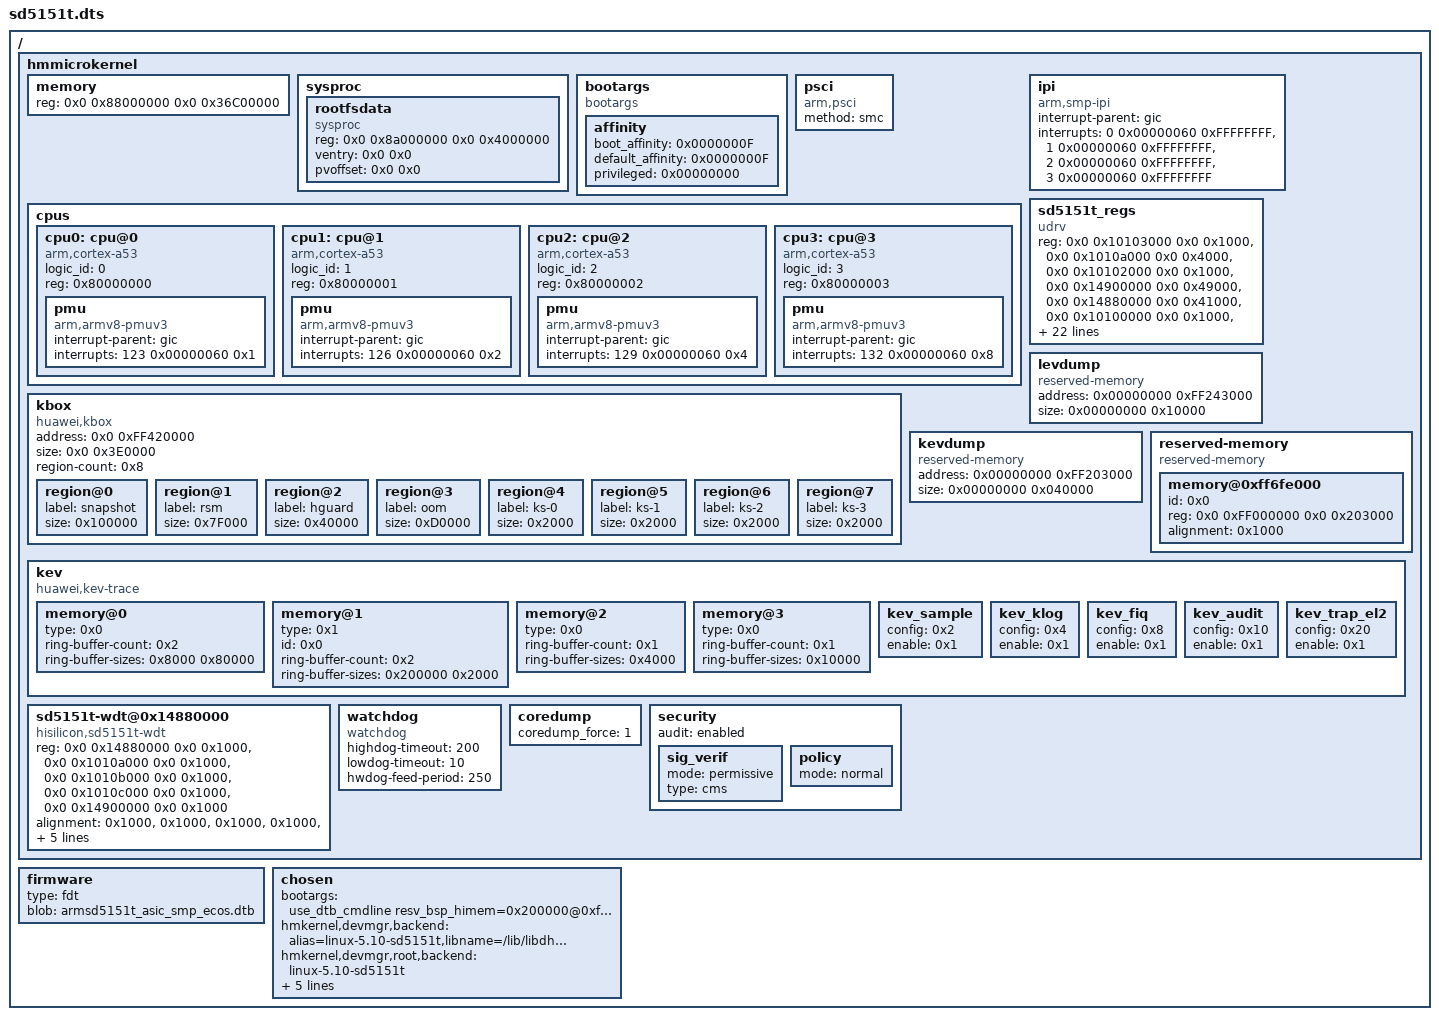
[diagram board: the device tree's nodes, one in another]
/*
 * Device Tree for SD5151T Board
 */

/dts-v1/;

/include/ "sd5151t.dtsi"
/ {
	hmmicrokernel {
		memory {
			device_type = "memory";
			/*
                         * deployment for physical memory
                         *
                         * +----------------+ 0xFFF00000
                         * | resv bsp himem | 1M
                         * +----------------+ 0xFFE00000
                         *         |
                         * +----------------+ 0xFF800000
                         * |     kbox       | 3968K
                         * +----------------+ 0xFF420000
                         * |     ekbox      | 128K
                         * +----------------+ 0xFF400000
                         * |     klog       | 4M
                         * +----------------+ 0xFF000000
                         * |     unused     | 4M
                         * +----------------+ 0xFEC00000
                         * |      shm       | 32M+8K+4K    -->0xFEC00000 -->0xFEC00000
                         * +----------------+ 0xFCBFD000          ^             ^
                         * |                | 1012K               |             |
                         * + third-party vm + 0xFCB00000        1024M           |
                         * | (guest mem01)  | 991M                |           1900M
                         * |                | (final: 1332M)      V             |
                         * +----------------+ 0xBEC00000   -->0xBEC00000        |
                         * |      host      | 876M                              |
                         * |  (include hpe) | (final: 567M)                     V
                         * +----------------+ 0x88000000 -->0x88000000 -->0x88000000
                         * |    lsw sdk     | 128M
                         * +----------------+ 0x80000000
                         */
			reg = <0x0 0x88000000 0x0 0x36C00000>;
		};

		sysproc {
			/* Describe board boot param rootfs in top level dts */
			rootfsdata {
				compatible = "sysproc", "rootfs";
				reg = <0x0 0x8a000000 0x0 0x4000000>;
				ventry = <0x0 0x0>;
				/* filled by bootloader */
				pvoffset = <0x0 0x0>;
			};
		};

		bootargs {
			compatible = "bootargs";
			affinity {
				boot_affinity = <0x0000000F>;			/* CPU 0, 1, 2, 3 */
				default_affinity = <0x0000000F>;		/* CPU 0, 1, 2, 3 */
				privileged = <0x00000000>;		/* no privileged_affinity in default */
			};
		};

		psci {
			compatible = "arm,psci";
			method = "smc";
		};

		cpus {
			#address-cells = <1>;
			#size-cells = <0>;

			cpu0: cpu@0 {
				compatible = "arm,cortex-a53", "arm,armv8";
				device_type = "cpu";
				logic_id = <0>;
				reg = <0x80000000>;
				pmu {
					compatible = "arm,armv8-pmuv3";
					interrupt-parent = <&gic>;
					/* SPI 64: PMUIRQ, group default, prio:0x60 */
					interrupts = <123 0x00000060 0x1>;
				};
			};
			cpu1: cpu@1 {
				compatible = "arm,cortex-a53", "arm,armv8";
				device_type = "cpu";
				logic_id = <1>;
				reg = <0x80000001>;
				pmu {
					compatible = "arm,armv8-pmuv3";
					interrupt-parent = <&gic>;
					interrupts = <126 0x00000060 0x2>;
				};
			};
			cpu2: cpu@2 {
				compatible = "arm,cortex-a53", "arm,armv8";
				device_type = "cpu";
				logic_id = <2>;
				reg = <0x80000002>;
				pmu {
					compatible = "arm,armv8-pmuv3";
					interrupt-parent = <&gic>;
					interrupts = <129 0x00000060 0x4>;
				};
			};
			cpu3: cpu@3 {
				compatible = "arm,cortex-a53", "arm,armv8";
				device_type = "cpu";
				logic_id = <3>;
				reg = <0x80000003>;
				pmu {
					compatible = "arm,armv8-pmuv3";
					interrupt-parent = <&gic>;
					interrupts = <132 0x00000060 0x8>;
				};
			};
		};

		ipi {
			/* smp ipi */
			compatible = "arm,smp-ipi";

			interrupt-parent = <&gic>;

			/* interrupt settings:
			 * 1st cell: real hardware irq number
			 *     ARM recommendation: ID 0-7 for Non-Secure;
			 *                         ID 8-15 for Secure Interrupt
			 * 2nd cell: interrupt config
			 *     bit [27:26]: Group setting
			 *     bit [24]: Trigger Type
			 *     bit [23:8]: Reserved
			 *     bit [7:0]: Priority
			 * 3rd cell: interrupt target config
			 *     Warning: Send to all cpus by default
			 */
			interrupts =	<0 0x00000060 0xFFFFFFFF>, /* IPI_RESCHEDULE */
					<1 0x00000060 0xFFFFFFFF>, /* IPI_CALL_FUNC */
					<2 0x00000060 0xFFFFFFFF>, /* IPI_CPU_STOP */
					<3 0x00000060 0xFFFFFFFF>; /* IPI_VNOTIFY */
		};

		sd5151t_regs {
			compatible = "udrv";
			#address-cells = <2>;
			#size-cells = <2>;
			reg =	<0x0 0x10103000 0x0 0x1000>, /* timer */
				<0x0 0x1010a000 0x0 0x4000>, /* gpio */
				<0x0 0x10102000 0x0 0x1000>, /* bus_timer */
				<0x0 0x14900000 0x0 0x49000>,
				<0x0 0x14880000 0x0 0x41000>,
				<0x0 0x10100000 0x0 0x1000>,
				<0x0 0x10120000 0x0 0x2000>,
				<0x0 0x10121000 0x0 0x1000>, /* i2c */
				<0x0 0x10144000 0x0 0x10000>,
				<0x0 0x30000000 0x0 0x400000>,
				<0x0 0x48000000 0x0 0x400000>,
				<0x0 0x1014c000 0x0 0x10000>,
				<0x0 0x14880000 0x0 0x1000>,
				<0x0 0x14900000 0x0 0x1000>,
				<0x0 0x60000000 0x0 0x400000>, /* pcie */
				<0x0 0x15200000 0x0 0x1000>,
				<0x0 0x14880000 0x0 0x1000>, /* ata */
				<0x0 0xFF420000 0x0 0x003E0000>, /* kbox */
				<0x0 0xFF243000 0x0 0x10000>, /* levdump */
				<0x0 0xFF203000 0x0 0x40000>, /* kevdump */
				<0x0 0xff800000 0x0 0x800000>, /* bsp_himem */
				<0x0 0x10000000 0x0 0x6000000>, /* sdk */
				<0x0 0x10700000 0x0 0x10000>,
				<0x0 0x10900000 0x0 0x100000>, /* FMC */
				<0x0 0x10100000 0x0 0x6000000>, /* fmea */
				<0x0 0x50100000 0x0 0x2000>,
				<0x0 0x10106000 0x0 0x4000>, /* uart0-uart3 */
				<0x0 0x15100000 0x0 0x100000>; /* usb3.0 */
		};

		kbox {
			compatible = "huawei,kbox";
			address = <0x0 0xFF420000>;
			size = <0x0 0x3E0000>;
			region-count= <0x8>;
			region@0 {
				label = "snapshot";
				size = <0x100000>;
			};
			region@1 {
				label = "rsm";
				size = <0x7F000>;
			};
			region@2 {
				label = "hguard";
				size = <0x40000>;
			};
			region@3 {
				label = "oom";
				size = <0xD0000>;
			};
			region@4 {
				label = "ks-0";
				size = <0x2000>;
			};
			region@5 {
				label = "ks-1";
				size = <0x2000>;
			};
			region@6 {
				label = "ks-2";
				size = <0x2000>;
			};
			region@7 {
				label = "ks-3";
				size = <0x2000>;
			};
		};

		levdump {
			compatible = "reserved-memory";
			address = <0x00000000 0xFF243000>;
			size = <0x00000000 0x10000>;
		};

		kevdump {
			compatible = "reserved-memory";
			address = <0x00000000 0xFF203000>;
			size = <0x00000000 0x040000>;
		};

		reserved-memory {
			compatible = "reserved-memory";
			#address-cells = <2>;
			#size-cells = <2>;
			memory@0xff6fe000 {
				id = <0x0>;
				reg = <0x0 0xFF000000 0x0 0x203000>;
				alignment = <0x1000>;
			};
		};

		kev {
			compatible = "huawei,kev-trace";

			memory@0 {
				type = <0x0>;
				ring-buffer-count = <0x2>;
				/*
				 * ring buffer 0: 32K
				 * ring buffer 1: 512K (sample)
				 */
				ring-buffer-sizes = <0x8000 0x80000>;
			};

			memory@1 {
				type = <0x1>; /* reserved memory */
				id = <0x0>;
				ring-buffer-count = <0x2>;
				/*
				 * Only ring buffer DATA sizes. Memory head and ring
				 * buffer heads are not included.
				 * ring buffer 2: 2MB(klog)
				 * ring buffer 3: 8K(fiq)
				 */
				ring-buffer-sizes = <0x200000 0x2000>;
			};

			memory@2 {
				type = <0x0>;
				ring-buffer-count = <0x1>;
				/*
				 * ring buffer 4: 16K(audit)
				 */
				ring-buffer-sizes = <0x4000>;
			};

			memory@3 {
				type = <0x0>; /* normal memory */
				ring-buffer-count = <0x1>;
				/*
				 * ring buffer 5: 64K(trap_el2)
				 */
				ring-buffer-sizes = <0x10000>;
			};

			kev_sample {
				config = <0x2>;
				enable = <0x1>;
			};
			kev_klog {
				config = <0x4>;
				enable = <0x1>;
			};
			kev_fiq {
				config = <0x8>;
				enable = <0x1>;
			};
			kev_audit {
				config = <0x10>;
				enable = <0x1>;
			};
			kev_trap_el2 {
				config = <0x20>;
				enable = <0x1>;
			};
		};

		/* SD5151T CPU watchdog */
		sd5151t-wdt@0x14880000 {
			compatible = "hisilicon,sd5151t-wdt";
			#address-cells = <2>;
			#size-cells = <2>;

			reg = <0x0 0x14880000 0x0 0x1000>,
			      /*
			       * SD5151T ext watchdog based on GPIO, cannot
			       * configure the timeout-sec for it.
			       */
			      <0x0 0x1010a000 0x0 0x1000>, /* GPIO  0 ~ 31 */
			      <0x0 0x1010b000 0x0 0x1000>, /* GPIO 32 ~ 63 */
			      <0x0 0x1010c000 0x0 0x1000>, /* GPIO 64 ~ 95 */
			      <0x0 0x14900000 0x0 0x1000>; /* IOMUX_DIO */
			alignment = <0x1000>, <0x1000>, <0x1000>, <0x1000>, <0x1000>;

			/*
			 * Configure the GPIO Pins for the SD5151T ext watchdog
			 *
			 * 1st cell: GPIO Pin for resetting the SD5151T ext watchdog.
			 *
			 * 2nd cell: GPIO Pin for triggering the interrupt when
			 *           the SD5151T ext watchdog timeout.
			 *
			 * 3rd cell: GPIO Pin for enabling the SD5151T ext watchdog.
			 *
			 * Currently the configurations for AR502H are <18 21 91>.
			 */
			ext-wdt-gpio = <18 21 91>;

			interrupt-parent = <&gic>;
			/*
			 * SGI number 6 is configured as a Group 0 interrupt in
			 * ATF. If the SD5151T ext watchdog timeout, It would be
			 * triggered to help the specific CPUs dump the lastword.
			 *
			 * SPI number 45 is triggered when the SD5151T ext watchdog
			 * timeout and configured as a Group 0 interrupt in ATF.
			 */
			interrupts = <6 0x00000060 0xFFFFFFFF>,  /* lastword ipi */
				     <45 0x00000060 0xFFFFFFFF>; /* gpio0_int */
		};
		watchdog {
			compatible = "watchdog";
			/* reserve 200s for hguard to take over the watchdog */
			highdog-timeout= <200>;
			/* reserve 10s for subcore to pull up*/
			lowdog-timeout = <10>;
			/* feed the hwdog every 250 ms */
			hwdog-feed-period = <250>;
		};
		coredump {
			coredump_force = <1>;
		};
		security {
			audit = "enabled";
			sig_verif {
				mode = "permissive";
				type = "cms";
			};
			policy {
				mode = "normal";
			};
		};
	};
	firmware {
		type = "fdt";
		blob = /incbin/("armsd5151t_asic_smp_ecos.dtb");
	};

	/* copy from "armsd5151t_asic_smp_ecos.dtb" */
	chosen {
		bootargs = "use_dtb_cmdline resv_bsp_himem=0x200000@0xffe00000 console=ttyAMA0,9600 root=/dev/ram0 rootfstype=ramfs initrd=0x8A000000,XXXXXX ekbox=0x20000$0xFF400000 kbox_mem=0x3e0000@0xFF420000,0x100000 renesas_usb_handoff_disable=1";

		/* config devhost backend */
		hmkernel,devmgr,backend =
			"alias=linux-5.10-sd5151t,libname=/lib/libdh-linux.so.5.10-sd5151t,modpath=/lib/modules/linux-5.10.0-sd5151t,default";

		/* config root devhost */
		hmkernel,devmgr,root,backend = "linux-5.10-sd5151t";
		hmkernel,devmgr,root,extensions = "lib/extension/libdhext_transfs.so",
						  "lib/extension/libdhext_vpipe.so";
		/* note: max limit length of transfs.ko args is 256 */
		hmkernel,devmgr,root,args = "transfs_page_clean_watermark=32000,transfs_page_sync_watermark=34000";
	};
};
